# BL808 register map
File version: 0.1
Registers are access not given, no defined reset value unless marked. A register's access mark holds for its fields unless they carry their own. Offsets are from the block's base; [hi:lo] are bit positions; {n}, {i} and the like mark numbered series.

## AON
Base 0x2000F000
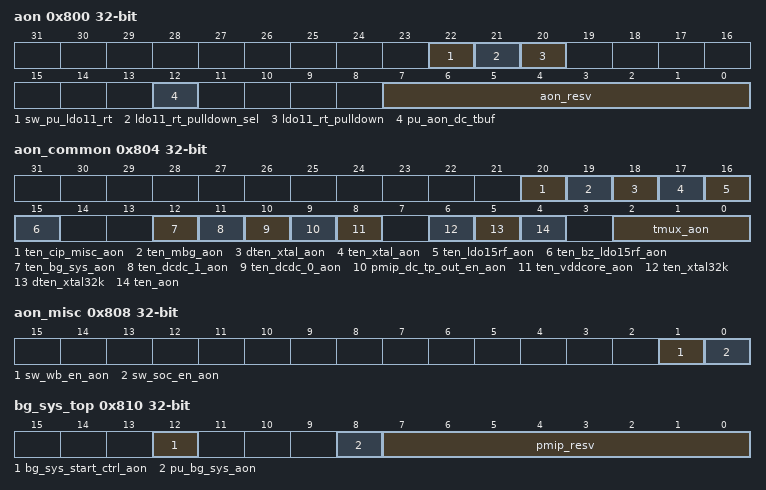
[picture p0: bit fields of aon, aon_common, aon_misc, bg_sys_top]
0x800 aon
  [22] sw_pu_ldo11_rt rw, [21] ldo11_rt_pulldown_sel rw, [20] ldo11_rt_pulldown rw, [12] pu_aon_dc_tbuf rw, [7:0] aon_resv rw
0x804 aon_common
  [20] ten_cip_misc_aon rw, [19] ten_mbg_aon rw, [18] dten_xtal_aon rw, [17] ten_xtal_aon rw, [16] ten_ldo15rf_aon rw, [15] ten_bz_ldo15rf_aon rw, [12] ten_bg_sys_aon rw, [11] ten_dcdc_1_aon rw, [10] ten_dcdc_0_aon rw, [9] pmip_dc_tp_out_en_aon rw, [8] ten_vddcore_aon rw, [6] ten_xtal32k rw, [5] dten_xtal32k rw, [4] ten_aon rw, [2:0] tmux_aon rw
0x808 aon_misc
  [1] sw_wb_en_aon rw, [0] sw_soc_en_aon rw
0x810 bg_sys_top
  [12] bg_sys_start_ctrl_aon rw, [8] pu_bg_sys_aon rw, [7:0] pmip_resv rw
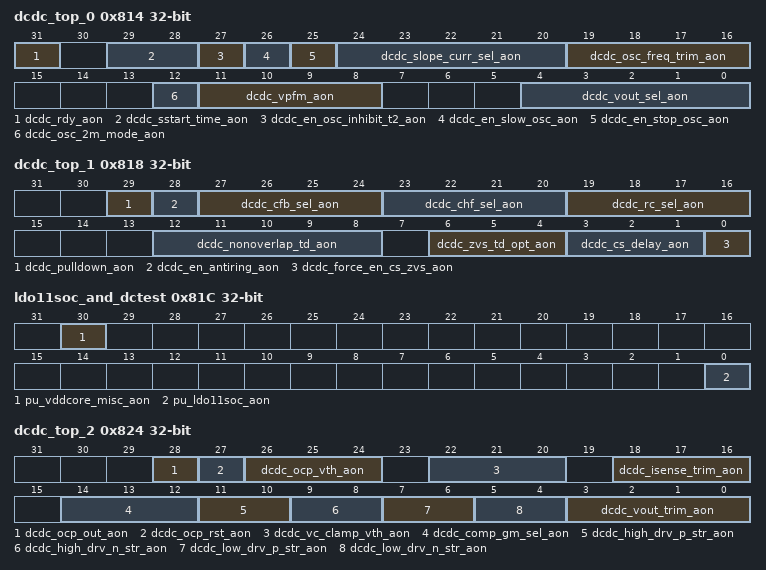
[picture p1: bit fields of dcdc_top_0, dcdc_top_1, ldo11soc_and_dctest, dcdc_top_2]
0x814 dcdc_top_0
  [31] dcdc_rdy_aon ro, [29:28] dcdc_sstart_time_aon rw, [27] dcdc_en_osc_inhibit_t2_aon rw, [26] dcdc_en_slow_osc_aon rw, [25] dcdc_en_stop_osc_aon rw, [24:20] dcdc_slope_curr_sel_aon rw, [19:16] dcdc_osc_freq_trim_aon rw, [12] dcdc_osc_2m_mode_aon rw, [11:8] dcdc_vpfm_aon rw, [4:0] dcdc_vout_sel_aon rw
0x818 dcdc_top_1
  [29] dcdc_pulldown_aon rw, [28] dcdc_en_antiring_aon rw, [27:24] dcdc_cfb_sel_aon rw, [23:20] dcdc_chf_sel_aon rw, [19:16] dcdc_rc_sel_aon rw, [12:8] dcdc_nonoverlap_td_aon rw, [6:4] dcdc_zvs_td_opt_aon rw, [3:1] dcdc_cs_delay_aon rw, [0] dcdc_force_en_cs_zvs_aon rw
0x81C ldo11soc_and_dctest
  [30] pu_vddcore_misc_aon rw, [0] pu_ldo11soc_aon rw
0x820 psw_irrcv
  [0] pu_ir_psw_aon rw
0x824 dcdc_top_2
  [28] dcdc_ocp_out_aon ro, [27] dcdc_ocp_rst_aon rw, [26:24] dcdc_ocp_vth_aon rw, [22:20] dcdc_vc_clamp_vth_aon rw, [18:16] dcdc_isense_trim_aon rw, [14:12] dcdc_comp_gm_sel_aon rw, [11:10] dcdc_high_drv_p_str_aon rw, [9:8] dcdc_high_drv_n_str_aon rw, [7:6] dcdc_low_drv_p_str_aon rw, [5:4] dcdc_low_drv_n_str_aon rw, [3:0] dcdc_vout_trim_aon rw
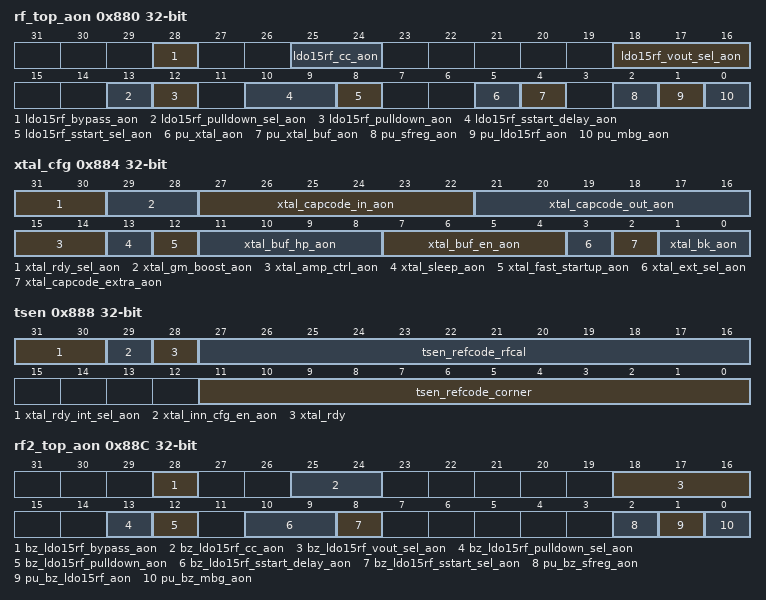
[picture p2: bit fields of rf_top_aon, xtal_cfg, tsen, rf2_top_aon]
0x880 rf_top_aon
  [28] ldo15rf_bypass_aon rw, [25:24] ldo15rf_cc_aon rw, [18:16] ldo15rf_vout_sel_aon rw, [13] ldo15rf_pulldown_sel_aon rw, [12] ldo15rf_pulldown_aon rw, [10:9] ldo15rf_sstart_delay_aon rw, [8] ldo15rf_sstart_sel_aon rw, [5] pu_xtal_aon rw, [4] pu_xtal_buf_aon rw, [2] pu_sfreg_aon rw, [1] pu_ldo15rf_aon rw, [0] pu_mbg_aon rw
0x884 xtal_cfg rw
  [31:30] xtal_rdy_sel_aon, [29:28] xtal_gm_boost_aon, [27:22] xtal_capcode_in_aon, [21:16] xtal_capcode_out_aon, [15:14] xtal_amp_ctrl_aon, [13] xtal_sleep_aon, [12] xtal_fast_startup_aon, [11:8] xtal_buf_hp_aon, [7:4] xtal_buf_en_aon, [3] xtal_ext_sel_aon, [2] xtal_capcode_extra_aon, [1:0] xtal_bk_aon
0x888 tsen
  [31:30] xtal_rdy_int_sel_aon rw, [29] xtal_inn_cfg_en_aon rw, [28] xtal_rdy ro, [27:16] tsen_refcode_rfcal rw, [11:0] tsen_refcode_corner rw
0x88C rf2_top_aon
  [28] bz_ldo15rf_bypass_aon rw, [25:24] bz_ldo15rf_cc_aon rw, [18:16] bz_ldo15rf_vout_sel_aon rw, [13] bz_ldo15rf_pulldown_sel_aon rw, [12] bz_ldo15rf_pulldown_aon rw, [10:9] bz_ldo15rf_sstart_delay_aon rw, [8] bz_ldo15rf_sstart_sel_aon rw, [2] pu_bz_sfreg_aon rw, [1] pu_bz_ldo15rf_aon rw, [0] pu_bz_mbg_aon rw
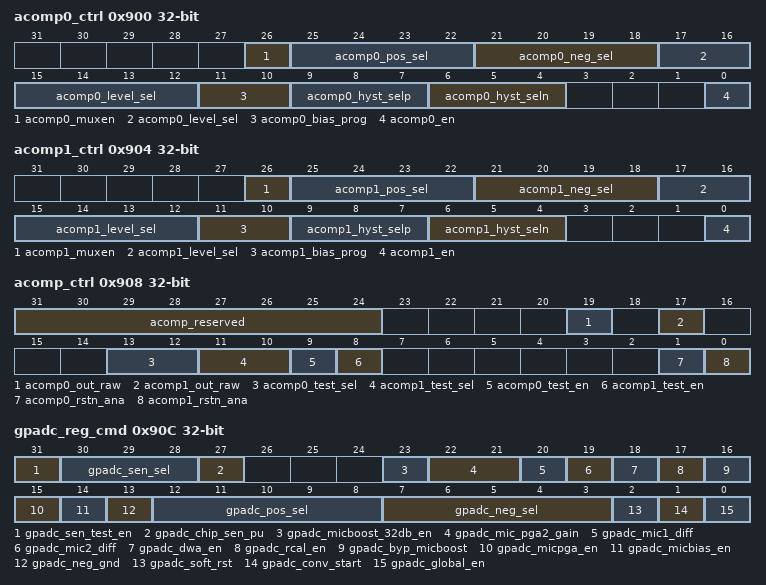
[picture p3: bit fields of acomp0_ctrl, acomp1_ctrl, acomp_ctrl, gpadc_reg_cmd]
0x900 acomp0_ctrl
  [26] acomp0_muxen rw, [25:22] acomp0_pos_sel rw, [21:18] acomp0_neg_sel rw, [17:12] acomp0_level_sel rw, [11:10] acomp0_bias_prog rw, [9:7] acomp0_hyst_selp rw, [6:4] acomp0_hyst_seln rw, [0] acomp0_en rw
0x904 acomp1_ctrl
  [26] acomp1_muxen rw, [25:22] acomp1_pos_sel rw, [21:18] acomp1_neg_sel rw, [17:12] acomp1_level_sel rw, [11:10] acomp1_bias_prog rw, [9:7] acomp1_hyst_selp rw, [6:4] acomp1_hyst_seln rw, [0] acomp1_en rw
0x908 acomp_ctrl
  [31:24] acomp_reserved rw, [19] acomp0_out_raw ro, [17] acomp1_out_raw ro, [13:12] acomp0_test_sel rw, [11:10] acomp1_test_sel rw, [9] acomp0_test_en rw, [8] acomp1_test_en rw, [1] acomp0_rstn_ana rw, [0] acomp1_rstn_ana rw
0x90C gpadc_reg_cmd
  [31] gpadc_sen_test_en rw, [30:28] gpadc_sen_sel rw, [27] gpadc_chip_sen_pu rw, [23] gpadc_micboost_32db_en rw, [22:21] gpadc_mic_pga2_gain rw, [20] gpadc_mic1_diff rw, [19] gpadc_mic2_diff rw, [18] gpadc_dwa_en rw, [17] gpadc_rcal_en rw, [16] gpadc_byp_micboost rw, [15] gpadc_micpga_en rw, [14] gpadc_micbias_en rw, [13] gpadc_neg_gnd rw, [12:8] gpadc_pos_sel rw, [7:3] gpadc_neg_sel rw, [2] gpadc_soft_rst rw, [1] gpadc_conv_start rw, [0] gpadc_global_en rw
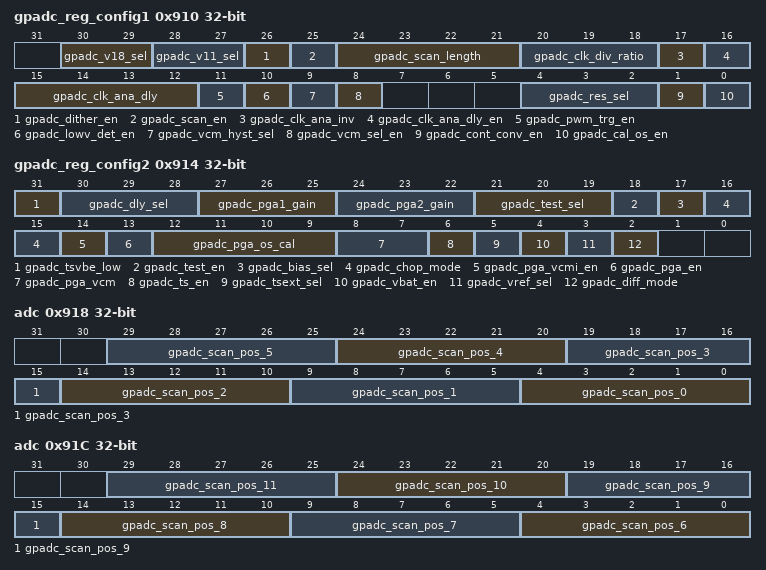
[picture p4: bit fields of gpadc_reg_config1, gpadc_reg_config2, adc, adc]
0x910 gpadc_reg_config1
  [30:29] gpadc_v18_sel rw, [28:27] gpadc_v11_sel rw, [26] gpadc_dither_en rw, [25] gpadc_scan_en rw, [24:21] gpadc_scan_length rw, [20:18] gpadc_clk_div_ratio rw, [17] gpadc_clk_ana_inv rw, [16] gpadc_clk_ana_dly_en rw, [15:12] gpadc_clk_ana_dly rw, [11] gpadc_pwm_trg_en rw, [10] gpadc_lowv_det_en rw, [9] gpadc_vcm_hyst_sel rw, [8] gpadc_vcm_sel_en rw, [4:2] gpadc_res_sel rw, [1] gpadc_cont_conv_en rw, [0] gpadc_cal_os_en rw
0x914 gpadc_reg_config2
  [31] gpadc_tsvbe_low rw, [30:28] gpadc_dly_sel rw, [27:25] gpadc_pga1_gain rw, [24:22] gpadc_pga2_gain rw, [21:19] gpadc_test_sel rw, [18] gpadc_test_en rw, [17] gpadc_bias_sel rw, [16:15] gpadc_chop_mode rw, [14] gpadc_pga_vcmi_en rw, [13] gpadc_pga_en rw, [12:9] gpadc_pga_os_cal rw, [8:7] gpadc_pga_vcm rw, [6] gpadc_ts_en rw, [5] gpadc_tsext_sel rw, [4] gpadc_vbat_en rw, [3] gpadc_vref_sel rw, [2] gpadc_diff_mode rw
0x918 adc converation sequence 1
  [5n+4:5n] gpadc_scan_pos_{n} rw (n=0..5)
0x91C adc converation sequence 2
  [5n-26:5n-30] gpadc_scan_pos_{n} rw (n=6..11)
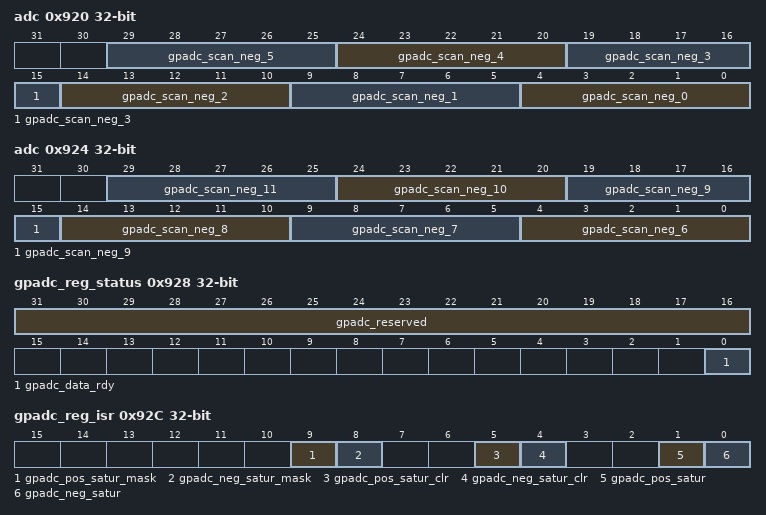
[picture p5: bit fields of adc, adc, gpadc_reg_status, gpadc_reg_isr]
0x920 adc converation sequence 3
  [5n+4:5n] gpadc_scan_neg_{n} rw (n=0..5)
0x924 adc converation sequence 4
  [5n-26:5n-30] gpadc_scan_neg_{n} rw (n=6..11)
0x928 gpadc_reg_status
  [31:16] gpadc_reserved rw, [0] gpadc_data_rdy ro
0x92C gpadc_reg_isr
  [9] gpadc_pos_satur_mask rw, [8] gpadc_neg_satur_mask rw, [5] gpadc_pos_satur_clr rw, [4] gpadc_neg_satur_clr rw, [1] gpadc_pos_satur ro, [0] gpadc_neg_satur ro
0x930 gpadc_reg_result
  [25:0] gpadc_data_out ro
0x934 gpadc_reg_raw_result
  [11:0] gpadc_raw_data ro
0x938 gpadc_reg_define
  [15:0] gpadc_os_cal_data rw
0x93C hbncore_resv0 rw
  [31:0] hbncore_resv0_data
0x940 hbncore_resv1 rw
  [31:0] hbncore_resv1_data
